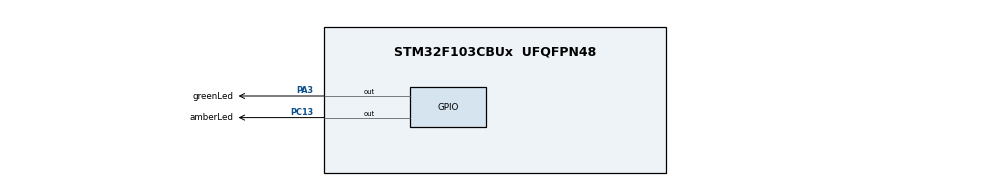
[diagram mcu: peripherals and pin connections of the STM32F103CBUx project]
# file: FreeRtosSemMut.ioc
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FREERTOS.CountingSemaphores01=slotSem,5,Dynamic,NULL
FREERTOS.Mutexes01=qMut
FREERTOS.Tasks01=defaultTask,0,128,StartDefaultTask,Default,NULL
FREERTOS.configUSE_COUNTING_SEMAPHORES=1
Mcu.Family=STM32F1
Mcu.Name=STM32F103CBUx
Mcu.Package=UFQFPN48
NVIC.PriorityGroup=NVIC_PRIORITYGROUP_4
NVIC.TIM3_IRQn=true\:0\:0\:false\:false\:true\:false
NVIC.TimeBase=TIM3_IRQn
NVIC.TimeBaseIP=TIM3
PA13.Mode=Serial_Wire
PA13.Signal=SYS_JTMS-SWDIO
PA14.Mode=Serial_Wire
PA14.Signal=SYS_JTCK-SWCLK
PA3.GPIO_Label=greenLed
PA3.Signal=GPIO_Output
PC13-TAMPER-RTC.GPIO_Label=amberLed
PC13-TAMPER-RTC.Signal=GPIO_Output
PD0-OSC_IN.Mode=HSE-External-Oscillator
PD0-OSC_IN.Signal=RCC_OSC_IN
PD1-OSC_OUT.Mode=HSE-External-Oscillator
PD1-OSC_OUT.Signal=RCC_OSC_OUT
ProjectManager.HeapSize=0x200
ProjectManager.StackSize=0x400
ProjectManager.TargetToolchain=SW4STM32
RCC.APB1Freq_Value=8000000
RCC.APB2Freq_Value=8000000
VP_FREERTOS_VS_ENABLE.Mode=Enabled
VP_SYS_VS_tim3.Mode=TIM3
board=FreeRtosSemMut

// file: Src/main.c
/**
  ******************************************************************************
  * File Name          : main.c
  * Description        : Main program body
  ******************************************************************************
  * This notice applies to any and all portions of this file
  * that are not between comment pairs USER CODE BEGIN and
  * USER CODE END. Other portions of this file, whether
  * inserted by the user or by software development tools
  * are owned by their respective copyright owners.
  *
  * Copyright (c) 2017 STMicroelectronics International N.V.
  * All rights reserved.
  *
  * Redistribution and use in source and binary forms, with or without
  * modification, are permitted, provided that the following conditions are met:
  *
  * 1. Redistribution of source code must retain the above copyright notice,
  *    this list of conditions and the following disclaimer.
  * 2. Redistributions in binary form must reproduce the above copyright notice,
  *    this list of conditions and the following disclaimer in the documentation
  *    and/or other materials provided with the distribution.
  * 3. Neither the name of STMicroelectronics nor the names of other
  *    contributors to this software may be used to endorse or promote products
  *    derived from this software without specific written permission.
  * 4. This software, including modifications and/or derivative works of this
  *    software, must execute solely and exclusively on microcontroller or
  *    microprocessor devices manufactured by or for STMicroelectronics.
  * 5. Redistribution and use of this software other than as permitted under
  *    this license is void and will automatically terminate your rights under
  *    this license.
  *
  * THIS SOFTWARE IS PROVIDED BY STMICROELECTRONICS AND CONTRIBUTORS "AS IS"
  * AND ANY EXPRESS, IMPLIED OR STATUTORY WARRANTIES, INCLUDING, BUT NOT
  * LIMITED TO, THE IMPLIED WARRANTIES OF MERCHANTABILITY, FITNESS FOR A
  * PARTICULAR PURPOSE AND NON-INFRINGEMENT OF THIRD PARTY INTELLECTUAL PROPERTY
  * RIGHTS ARE DISCLAIMED TO THE FULLEST EXTENT PERMITTED BY LAW. IN NO EVENT
  * SHALL STMICROELECTRONICS OR CONTRIBUTORS BE LIABLE FOR ANY DIRECT, INDIRECT,
  * INCIDENTAL, SPECIAL, EXEMPLARY, OR CONSEQUENTIAL DAMAGES (INCLUDING, BUT NOT
  * LIMITED TO, PROCUREMENT OF SUBSTITUTE GOODS OR SERVICES; LOSS OF USE, DATA,
  * OR PROFITS; OR BUSINESS INTERRUPTION) HOWEVER CAUSED AND ON ANY THEORY OF
  * LIABILITY, WHETHER IN CONTRACT, STRICT LIABILITY, OR TORT (INCLUDING
  * NEGLIGENCE OR OTHERWISE) ARISING IN ANY WAY OUT OF THE USE OF THIS SOFTWARE,
  * EVEN IF ADVISED OF THE POSSIBILITY OF SUCH DAMAGE.
  *
  ******************************************************************************
  */
#include "main.h"
#include "stm32f1xx_hal.h"
#include "cmsis_os.h"

osThreadId defaultTaskHandle;

osSemaphoreId slotSemHandle;
osMutexId qMutHandle;

/* USER CODE BEGIN PV */
/* Private variables ---------------------------------------------------------*/
osThreadId Task01Handle;
osThreadId Task02Handle;
/* USER CODE END PV */

void SystemClock_Config(void);
static void MX_GPIO_Init(void);
void StartDefaultTask(void const * argument);

/* USER CODE BEGIN PFP */
/* Private function prototypes -----------------------------------------------*/
void StartTask01(void const * argument);
void StartTask02(void const * argument);
/* USER CODE END PFP */

int main(void)
{

  /* MCU Configuration----------------------------------------------------------*/

  /* Reset of all peripherals, Initializes the Flash interface and the Systick. */
  HAL_Init();

  /* Configure the system clock */
  SystemClock_Config();

  /* Initialize all configured peripherals */
  MX_GPIO_Init();

  /* Create the mutex(es) */
  /* definition and creation of qMut */
//  osMutexDef(qMut);
//  qMutHandle = osMutexCreate(osMutex(qMut));

  /* Create the semaphores(s) */
  /* definition and creation of slotSem */
//  osSemaphoreDef(slotSem);
//  slotSemHandle = osSemaphoreCreate(osSemaphore(slotSem), 5);

  /* USER CODE BEGIN RTOS_SEMAPHORES */
//  qMutHandle = xSemaphoreCreateMutex();
//  slotSemHandle = xSemaphoreCreateCounting(5, 0);
  qMutHandle = xQueueCreateMutex(queueQUEUE_TYPE_MUTEX);
  /* USER CODE END RTOS_SEMAPHORES */

  /* Create the thread(s) */
  /* definition and creation of defaultTask */
  osThreadDef(defaultTask, StartDefaultTask, osPriorityNormal, 0, 128);
  defaultTaskHandle = osThreadCreate(osThread(defaultTask), NULL);

  /* USER CODE BEGIN RTOS_THREADS */
  /* definition and creation of Task01 */
  osThreadDef(task01, StartTask01, osPriorityNormal, 0, 256);
  Task01Handle = osThreadCreate(osThread(task01), NULL);

  /* definition and creation of Task02 */
  osThreadDef(task02, StartTask02, osPriorityNormal, 0, 128);
  Task02Handle = osThreadCreate(osThread(task02), NULL);
  /* USER CODE END RTOS_THREADS */

  /* Start scheduler */
  osKernelStart();

  /* We should never get here as control is now taken by the scheduler */

  /* Infinite loop */
  while (1)
  {

  }

}

/** System Clock Configuration
*/
void SystemClock_Config(void)
{

  RCC_OscInitTypeDef RCC_OscInitStruct;
  RCC_ClkInitTypeDef RCC_ClkInitStruct;

    /**Initializes the CPU, AHB and APB busses clocks
    */
  RCC_OscInitStruct.OscillatorType = RCC_OSCILLATORTYPE_HSI;
  RCC_OscInitStruct.HSIState = RCC_HSI_ON;
  RCC_OscInitStruct.HSICalibrationValue = 16;
  RCC_OscInitStruct.PLL.PLLState = RCC_PLL_NONE;
  if (HAL_RCC_OscConfig(&RCC_OscInitStruct) != HAL_OK)
  {
    _Error_Handler(__FILE__, __LINE__);
  }

    /**Initializes the CPU, AHB and APB busses clocks
    */
  RCC_ClkInitStruct.ClockType = RCC_CLOCKTYPE_HCLK|RCC_CLOCKTYPE_SYSCLK
                              |RCC_CLOCKTYPE_PCLK1|RCC_CLOCKTYPE_PCLK2;
  RCC_ClkInitStruct.SYSCLKSource = RCC_SYSCLKSOURCE_HSI;
  RCC_ClkInitStruct.AHBCLKDivider = RCC_SYSCLK_DIV1;
  RCC_ClkInitStruct.APB1CLKDivider = RCC_HCLK_DIV1;
  RCC_ClkInitStruct.APB2CLKDivider = RCC_HCLK_DIV1;

  if (HAL_RCC_ClockConfig(&RCC_ClkInitStruct, FLASH_LATENCY_0) != HAL_OK)
  {
    _Error_Handler(__FILE__, __LINE__);
  }

    /**Configure the Systick interrupt time
    */
  HAL_SYSTICK_Config(HAL_RCC_GetHCLKFreq()/1000);

    /**Configure the Systick
    */
  HAL_SYSTICK_CLKSourceConfig(SYSTICK_CLKSOURCE_HCLK);

  /* SysTick_IRQn interrupt configuration */
  HAL_NVIC_SetPriority(SysTick_IRQn, 15, 0);
}

/** Configure pins as
        * Analog
        * Input
        * Output
        * EVENT_OUT
        * EXTI
*/
static void MX_GPIO_Init(void)
{

  GPIO_InitTypeDef GPIO_InitStruct;

  /* GPIO Ports Clock Enable */
  __HAL_RCC_GPIOC_CLK_ENABLE();
  __HAL_RCC_GPIOD_CLK_ENABLE();
  __HAL_RCC_GPIOA_CLK_ENABLE();

  /*Configure GPIO pin Output Level */
  HAL_GPIO_WritePin(amberLed_GPIO_Port, amberLed_Pin, GPIO_PIN_RESET);

  /*Configure GPIO pin Output Level */
  HAL_GPIO_WritePin(greenLed_GPIO_Port, greenLed_Pin, GPIO_PIN_RESET);

  /*Configure GPIO pin : amberLed_Pin */
  GPIO_InitStruct.Pin = amberLed_Pin;
  GPIO_InitStruct.Mode = GPIO_MODE_OUTPUT_PP;
  GPIO_InitStruct.Speed = GPIO_SPEED_FREQ_LOW;
  HAL_GPIO_Init(amberLed_GPIO_Port, &GPIO_InitStruct);

  /*Configure GPIO pin : greenLed_Pin */
  GPIO_InitStruct.Pin = greenLed_Pin;
  GPIO_InitStruct.Mode = GPIO_MODE_OUTPUT_PP;
  GPIO_InitStruct.Speed = GPIO_SPEED_FREQ_LOW;
  HAL_GPIO_Init(greenLed_GPIO_Port, &GPIO_InitStruct);

}

/* USER CODE BEGIN 4 */
void StartTask01(void const * argument) {

//  osSemaphoreWait(slotSemHandle, 0);
//  xSemaphoreTake(slotSemHandle, portMAX_DELAY);
  while(1) {
    osMutexWait(qMutHandle, osWaitForever);
    HAL_GPIO_TogglePin(amberLed_GPIO_Port, amberLed_Pin);
    HAL_Delay(100);
    HAL_GPIO_TogglePin(amberLed_GPIO_Port, amberLed_Pin);
    osMutexRelease(qMutHandle);
    HAL_Delay(100);
  }
}

void StartTask02(void const * argument) {
  int i = 0;
  while(1) {
    HAL_GPIO_TogglePin(greenLed_GPIO_Port, greenLed_Pin);
    HAL_Delay(500);
    /*
    if(i++ == 10) {
      xSemaphoreGive(slotSemHandle);
    }
     */
    if(i++ == 0) {
      osMutexWait(qMutHandle, osWaitForever);
    } else if(i == 10) {
      osMutexRelease(qMutHandle);
    } else if(i == 20) {
      i = 0;
    }

  }
}
/* USER CODE END 4 */

/* StartDefaultTask function */
void StartDefaultTask(void const * argument)
{

  for(;;)
  {
    osDelay(1);
  }
}

void HAL_TIM_PeriodElapsedCallback(TIM_HandleTypeDef *htim)
{
  if (htim->Instance == TIM3) {
    HAL_IncTick();
  }
}

void _Error_Handler(char * file, int line)
{
  while(1)
  {
  }
}

/************************ (C) COPYRIGHT STMicroelectronics *****END OF FILE****/
